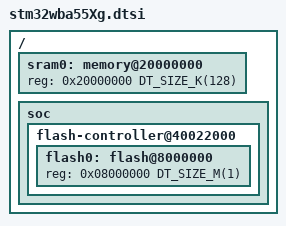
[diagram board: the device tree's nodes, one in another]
/*
 * Copyright (c) 2023 STMicroelectronics
 *
 * SPDX-License-Identifier: Apache-2.0
 */
#include <st/wba/stm32wba55.dtsi>

/ {
	sram0: memory@20000000 {
		reg = <0x20000000 DT_SIZE_K(128)>;
	};

	soc {
		flash-controller@40022000 {
			flash0: flash@8000000 {
				reg = <0x08000000 DT_SIZE_M(1)>;
				ranges = <0x0 0x8000000 DT_SIZE_M(1)>;
				#address-cells = <1>;
				#size-cells = <1>;
			};
		};
	};
};
